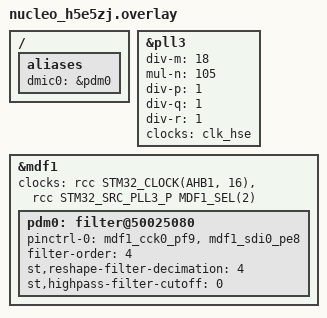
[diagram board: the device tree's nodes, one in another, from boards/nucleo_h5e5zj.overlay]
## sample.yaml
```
sample:
  name: DMIC sample
tests:
  sample.drivers.audio.dmic:
    tags: dmic
    filter: dt_nodelabel_enabled("dmic_dev")
    integration_platforms:
      - nrf52840dk/nrf52840
      - nrf5340dk/nrf5340/cpuapp
      - nrf54l15dk/nrf54l15/cpuapp
      - apollo510_evb
      - stm32f769i_disco
      - nucleo_f767zi
    harness: console
    harness_config:
      type: multi_line
      ordered: true
      regex:
        - "DMIC sample"
        - "Exiting"
```

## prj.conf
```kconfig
CONFIG_AUDIO=y
CONFIG_AUDIO_DMIC=y

CONFIG_LOG=y
CONFIG_AUDIO_DMIC_LOG_LEVEL_DBG=y
CONFIG_AUDIO_DMIC_SHELL=y
CONFIG_SHELL=y
```

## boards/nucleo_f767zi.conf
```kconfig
# SPDX-FileCopyrightText: Copyright (c) 2026 STMicroelectronics
# SPDX-License-Identifier: Apache-2.0

CONFIG_HW_CHANNEL_INDEX=1
```

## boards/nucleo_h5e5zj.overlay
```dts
/*
 * SPDX-FileCopyrightText: Copyright (c) 2026 STMicroelectronics
 * SPDX-License-Identifier: Apache-2.0
 */

/ {
	aliases {
		dmic0 = &pdm0;
	};
};

/*
 * MDF1:
 * PLL3_P selected as input audio clock.
 *
 * f_PLL3_p = 280 MHz (48 MHz * 105 / (18 * 1))
 */
&pll3 {
	div-m = <18>;
	mul-n = <105>;
	div-p = <1>;
	div-q = <1>;
	div-r = <1>;
	clocks = <&clk_hse>;
	status = "okay";
};

&mdf1 {
	clocks = <&rcc STM32_CLOCK(AHB1, 16)>,
		<&rcc STM32_SRC_PLL3_P MDF1_SEL(2)>;
	clock-names = "pclk", "aclk";
	status = "okay";

	pdm0: filter@50025080 {
		pinctrl-0 = <&mdf1_cck0_pf9
			     &mdf1_sdi0_pe8>;
		pinctrl-names = "default";
		filter-order = <4>;
		st,reshape-filter-decimation = <4>;
		st,highpass-filter-cutoff = <0>;
		status = "okay";
	};
};
```

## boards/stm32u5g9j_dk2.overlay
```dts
/*
 * SPDX-FileCopyrightText: Copyright (c) 2026 STMicroelectronics
 * SPDX-License-Identifier: Apache-2.0
 */

/ {
	aliases {
		dmic0 = &pdm0;
	};
};

/*
 * MDF1:
 * PLL3_Q selected as input audio clock.
 *
 * f_PLL3 = 500 MHz (16 MHz * 125 / 4)
 * f_PLL3Q = 500 MHz
 */
&pll3 {
	div-m = <4>;
	mul-n = <125>;
	div-p = <20>;
	div-q = <20>;
	div-q = <1>;
	div-r = <20>;
	clocks = <&clk_hse>;
	status = "okay";
};

&mdf1 {
	clocks = <&rcc STM32_CLOCK(AHB1, 3)>,
		<&rcc STM32_SRC_PLL3_Q MDF1_SEL(2)>;
	clock-names = "pclk", "aclk";
	status = "okay";

	pdm0: filter@40025080{
		pinctrl-0 = <&mdf1_cck0_pb8
			     &mdf1_sdi0_pb1>;
		pinctrl-names = "default";
		filter-order = <4>;
		st,reshape-filter-decimation = <4>;
		st,highpass-filter-cutoff = <0>;
		status = "okay";
	};
};
```

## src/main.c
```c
/*
 * Copyright (c) 2021 Nordic Semiconductor ASA
 *
 * SPDX-License-Identifier: Apache-2.0
 */

#include <zephyr/kernel.h>
#include <zephyr/audio/dmic.h>

#include <zephyr/logging/log.h>
LOG_MODULE_REGISTER(dmic_sample);

#define MAX_SAMPLE_RATE  16000
#define SAMPLE_BIT_WIDTH CONFIG_SAMPLE_BIT_WIDTH
#define PDM_CTL_IDX      CONFIG_HW_CHANNEL_INDEX
#define BYTES_PER_SAMPLE SAMPLE_BIT_WIDTH / 8
/* Milliseconds to wait for a block to be read. */
#define READ_TIMEOUT     1000

/* Size of a block for 100 ms of audio data. */
#define BLOCK_SIZE(_sample_rate, _number_of_channels) \
	(BYTES_PER_SAMPLE * (_sample_rate / 10) * _number_of_channels)

/* Driver will allocate blocks from this slab to receive audio data into them.
 * Application, after getting a given block from the driver and processing its
 * data, needs to free that block.
 */
#define MAX_BLOCK_SIZE   BLOCK_SIZE(MAX_SAMPLE_RATE, 2)
#define BLOCK_COUNT      4
K_MEM_SLAB_DEFINE_STATIC(mem_slab, MAX_BLOCK_SIZE, BLOCK_COUNT, 4);

static uint8_t capture_storage[BLOCK_COUNT * MAX_BLOCK_SIZE * 2];

static int do_pdm_transfer(const struct device *dmic_dev,
			   struct dmic_cfg *cfg,
			   size_t block_count)
{
	int ret;

	LOG_INF("PCM output rate: %u, channels: %u",
		cfg->streams[0].pcm_rate, cfg->channel.req_num_chan);

	ret = dmic_configure(dmic_dev, cfg);
	if (ret < 0) {
		LOG_ERR("Failed to configure the driver: %d", ret);
		return ret;
	}

	ret = dmic_trigger(dmic_dev, DMIC_TRIGGER_START);
	if (ret < 0) {
		LOG_ERR("START trigger failed: %d", ret);
		return ret;
	}

	for (int i = 0; i < block_count; ++i) {
		void *buffer;
		uint32_t size;

		ret = dmic_read(dmic_dev, 0, &buffer, &size, READ_TIMEOUT);
		if (ret < 0) {
			LOG_ERR("%d - read failed: %d", i, ret);
			return ret;
		}

		LOG_INF("%d - got buffer %p of %u bytes", i, buffer, size);

		if (size <= sizeof(capture_storage)) {
			memcpy(capture_storage + i * size, buffer, size);
		} else {
			LOG_ERR("capture_storage overflow");
		}
		k_mem_slab_free(&mem_slab, buffer);
	}

	ret = dmic_trigger(dmic_dev, DMIC_TRIGGER_STOP);
	if (ret < 0) {
		LOG_ERR("STOP trigger failed: %d", ret);
		return ret;
	}

	return ret;
}

int main(void)
{
	const struct device *const dmic_dev = DEVICE_DT_GET(DT_NODELABEL(dmic_dev));
	int ret;

	LOG_INF("DMIC sample");

	if (!device_is_ready(dmic_dev)) {
		LOG_ERR("%s is not ready", dmic_dev->name);
		return 0;
	}

	struct pcm_stream_cfg stream = {
		.pcm_width = SAMPLE_BIT_WIDTH,
		.mem_slab  = &mem_slab,
	};
	struct dmic_cfg cfg = {
		.io = {
			/* These fields can be used to limit the PDM clock
			 * configurations that the driver is allowed to use
			 * to those supported by the microphone.
			 */
			.min_pdm_clk_freq = 1000000,
			.max_pdm_clk_freq = 3500000,
			.min_pdm_clk_dc   = 40,
			.max_pdm_clk_dc   = 60,
		},
		.streams = &stream,
		.channel = {
			.req_num_streams = 1,
		},
	};

	cfg.channel.req_num_chan = 1;
	cfg.channel.req_chan_map_lo =
		dmic_build_channel_map(0, PDM_CTL_IDX, PDM_CHAN_LEFT);
	cfg.streams[0].pcm_rate = MAX_SAMPLE_RATE;
	cfg.streams[0].block_size =
		BLOCK_SIZE(cfg.streams[0].pcm_rate, cfg.channel.req_num_chan);

	ret = do_pdm_transfer(dmic_dev, &cfg, 2 * BLOCK_COUNT);
	if (ret < 0) {
		return 0;
	}

	cfg.channel.req_num_chan = 2;
	cfg.channel.req_chan_map_lo =
		dmic_build_channel_map(0, PDM_CTL_IDX, PDM_CHAN_LEFT) |
		dmic_build_channel_map(1, PDM_CTL_IDX, PDM_CHAN_RIGHT);
	cfg.streams[0].pcm_rate = MAX_SAMPLE_RATE;
	cfg.streams[0].block_size =
		BLOCK_SIZE(cfg.streams[0].pcm_rate, cfg.channel.req_num_chan);

	ret = do_pdm_transfer(dmic_dev, &cfg, 2 * BLOCK_COUNT);
	if (ret < 0) {
		return 0;
	}

	LOG_INF("Exiting");
	return 0;
}
```
